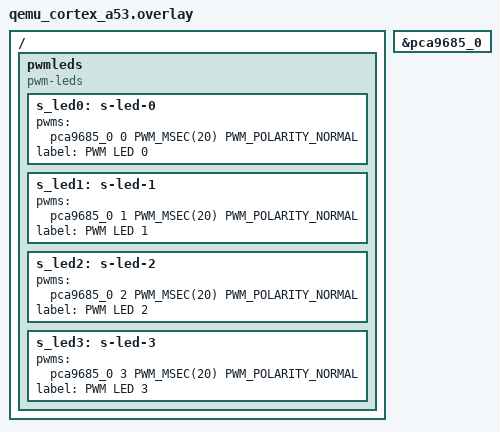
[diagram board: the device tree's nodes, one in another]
/*
 * Copyright (c) 2026
 * SPDX-License-Identifier: Apache-2.0
 *
 * samples/drivers/led/pwm: the PCA9685 alone, plus the pwm-leds the stock
 * sample binds with DT_COMPAT_GET_ANY_STATUS_OKAY(pwm_leds).
 * Requires -S virtio-i2c.
 */

#include <zephyr/dt-bindings/pwm/pwm.h>

&pca9685_0 {
	status = "okay";
};

/ {
	pwmleds {
		compatible = "pwm-leds";

		s_led0: s-led-0 {
			pwms = <&pca9685_0 0 PWM_MSEC(20) PWM_POLARITY_NORMAL>;
			label = "PWM LED 0";
		};
		s_led1: s-led-1 {
			pwms = <&pca9685_0 1 PWM_MSEC(20) PWM_POLARITY_NORMAL>;
			label = "PWM LED 1";
		};
		s_led2: s-led-2 {
			pwms = <&pca9685_0 2 PWM_MSEC(20) PWM_POLARITY_NORMAL>;
			label = "PWM LED 2";
		};
		s_led3: s-led-3 {
			pwms = <&pca9685_0 3 PWM_MSEC(20) PWM_POLARITY_NORMAL>;
			label = "PWM LED 3";
		};
	};
};
